# A31G12x_series register map
Vendor: ABOV Semiconductor Co., Ltd.; Series: A31G12x_series; File version: 1.0
CPU: CM0PLUS r0p1, little endian, no MPU, no FPU, VTOR, 2 interrupt priority bits
Registers are 32-bit, read-write, reset 0x0 unless marked. A register's access mark holds for its fields unless they carry their own. Offsets are from the block's base; [hi:lo] are bit positions.

## T30 — TIMER COUNTER 30
Base 0x40002400
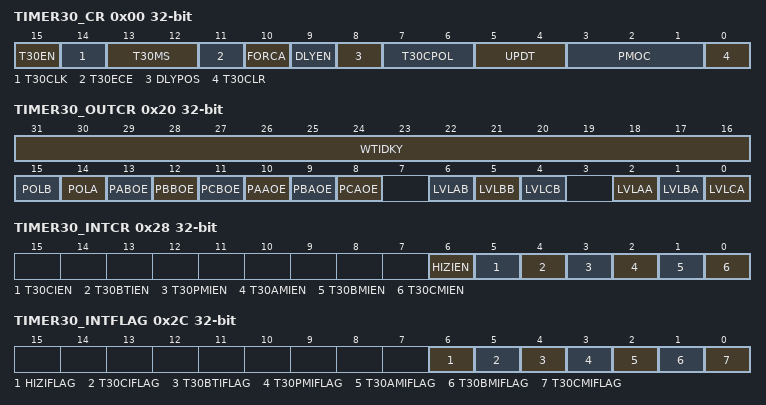
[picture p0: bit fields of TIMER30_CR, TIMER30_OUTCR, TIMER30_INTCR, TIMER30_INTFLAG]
0x00 TIMER30_CR — Timer/Counter 30 Control Register
  [15] T30EN — Timer 30 Operation Enable bit
    0=DISABLE_T30 (Disable timer 30 operation); 1=ENABLE_T30 (Enable timer 30 operation (Counter clear and start))
  [14] T30CLK — Timer 30 Clock Selection bit (Note: This bit should be changed during T30EN bit is "0b".)
    0=SELECT_INTERNAL_CLK (Select an internal prescaler clock); 1=SELECT_EXTERNAL_CLK (Select an external clock)
  [13:12] T30MS — Timer 30 Operation Mode Selection bits (Note: These bits should be changed during T30EN bit is "0b".)
    0=INTERVAL_MODE (Interval mode (All match interrupts can occur)); 1=CAPTURE_MODE (Capture mode (The Period-match interrupt can occur)); 2=BACK_TO_BACK_MODE (Back-to-back mode (All interrupts can occur))
  [11] T30ECE — Timer 30 External Clock Edge Selection bit
  [10] FORCA — Timer 30 Output Mode Selection bit. This bit should be changed when the T30EN is "0b". Note: If this bit is changed on operation, it shall apply from the next period.
  [9] DLYEN — Delay Time Insertion Enable bit
  [8] DLYPOS — Delay Time Insertion Position
  [7:6] T30CPOL — Timer 30 Capture Polarity Selection bits
  [5:4] UPDT — Data Reload Time Selection bits
  [3:1] PMOC — Period Match Interrupt Occurrence Selection (Note: A period match counter is cleared as 0x00 when the T3nCLR bit is set or the PMOC[2:0] bits are changed.)
  [0] T30CLR — Timer 30 Counter and Prescaler Clear bit
    0=LET_T30_CNT_BE (No effect); 1=CLEAR_T30_CNT (Clear timer 30 counter and prescaler (Automatically cleared to "0b" after operation))
0x04 TIMER30_PDR reset 0xFFFF — Timer/Counter 30 Period Data Register
  [15:0] PDATA — Timer/Counter 30 Period Data bits. The range is 0x0002 to 0xFFFF.
0x08 TIMER30_ADR reset 0xFFFF — Timer/Counter 30 A Data Register
  [15:0] ADATA — Timer/Counter 30 A Data bits. The range is 0x0000 to 0xFFFF.
0x0C TIMER30_BDR reset 0xFFFF — Timer/Counter 30 B Data Register
  [15:0] BDATA — Timer/Counter 30 B Data bits. The range is 0x0000 to 0xFFFF.
0x10 TIMER30_CDR reset 0xFFFF — Timer/Counter 30 C Data Register
  [15:0] CDATA — Timer/Counter 30 C Data bits. The range is 0x0000 to 0xFFFF.
0x14 TIMER30_CAPDR ro — Timer/Counter 30 Capture Data Register
  [15:0] CAPD — Timer/Counter 30 Capture Data bits.
0x18 TIMER30_PREDR reset 0xFFF — Timer/Counter 30 Prescaler Data Register
  [11:0] PRED — Timer/Counter 30 Prescaler Data bits.
0x1C TIMER30_CNT ro — Timer/Counter 30 Counter Register
  [15:0] CNT — Timer/Counter 30 Counter bits.
0x20 TIMER30_OUTCR (reset mask 0xFF77) — Timer/Counter 30 Output Control Register
  [31:16] WTIDKY wo — Write Identification Key. On writes, write 0xE06C to these bits, otherwise the write is ignored.
  [15] POLB — PWM30xB Output Polarity Selection bit
  [14] POLA — PWM30xA Output Polarity Selection bit
  [13] PABOE — PWM30AB Output Enable bit
  [12] PBBOE — PWM30BB Output Enable bit
  [11] PCBOE — PWM30CB Output Enable bit
  [10] PAAOE — PWM30AA Output Enable bit
  [9] PBAOE — PWM30BA Output Enable bit
  [8] PCAOE — PWM30CA Output Enable bit
  [6] LVLAB — Configure PWM30AB output When Disable
  [5] LVLBB — Configure PWM30BB output When Disable
  [4] LVLCB — Configure PWM30CB output When Disable
  [2] LVLAA — Configure PWM30AA output When Disable
  [1] LVLBA — Configure PWM30BA output When Disable
  [0] LVLCA — Configure PWM30CA output When Disable
0x24 TIMER30_DLY — Timer/Counter 30 PWM Output Delay Data Register
  [9:0] DLY — Timer/Counter 30 PWM Delay Data bits. Delay time: DLY[9:0]/fT30
0x28 TIMER30_INTCR — Timer/Counter 30 Interrupt Control Register
  [6] HIZIEN — Timer 30 Output High-Impedance Interrupt Enable bit
  [5] T30CIEN — Timer 30 Capture Interrupt Enable bit
  [4] T30BTIEN — Timer 30 Bottom Interrupt Enable bit
  [3] T30PMIEN — Timer 30 Period Match Interrupt Enable bit
  [2] T30AMIEN — Timer 30 A-ch Match Interrupt Enable bit
  [1] T30BMIEN — Timer 30 B-ch Match Interrupt Enable bit
  [0] T30CMIEN — Timer 30 C-ch Match Interrupt Enable bit
0x2C TIMER30_INTFLAG — Timer/Counter 30 Interrupt Flag Register
  [6] HIZIFLAG — Timer 30 Output High-Impedance Interrupt Flag bit
  [5] T30CIFLAG — Timer 30 Capture Interrupt Flag bit
  [4] T30BTIFLAG — Timer 30 Bottom Interrupt Flag bit
  [3] T30PMIFLAG — Timer 30 Period Match Interrupt Flag bit
  [2] T30AMIFLAG — Timer 30 A-ch Match Interrupt Flag bit
  [1] T30BMIFLAG — Timer 30 B-ch Match Interrupt Flag bit
  [0] T30CMIFLAG — Timer 30 C-ch Match Interrupt Flag bit
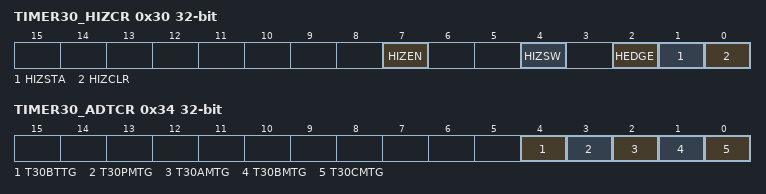
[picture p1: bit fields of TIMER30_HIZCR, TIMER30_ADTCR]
0x30 TIMER30_HIZCR — Timer/Counter 30 High-Impedance Control Register
  [7] HIZEN — PWM30xA/PWM30xB Output High-Impedance Enable bit
  [4] HIZSW — High-Impedance Output Software Setting
  [2] HEDGE — High-Impedance Edge Selection
  [1] HIZSTA ro — High-Impedance Status
  [0] HIZCLR — High-Impedance Output Clear bit
0x34 TIMER30_ADTCR — Timer/Counter 30 A/DC Trigger Control Register
  [4] T30BTTG — Select Timer 30 Bottom for A/DC Trigger Signal Generator
  [3] T30PMTG — Select Timer 30 Period Match for A/DC Trigger Signal Generator
  [2] T30AMTG — Select Timer 30 A-ch Match for A/DC Trigger Signal Generator
  [1] T30BMTG — Select Timer 30 B-ch Match for A/DC Trigger Signal Generator
  [0] T30CMTG — Select Timer 30 C-ch Match for A/DC Trigger Signal Generator
0x38 TIMER30_ADTDR — Timer/Counter 30 A/DC Trigger Generator Data Register
  [13:0] ADTDATA — Timer/Counter 30 A/DC Trigger Generation Data bits.
